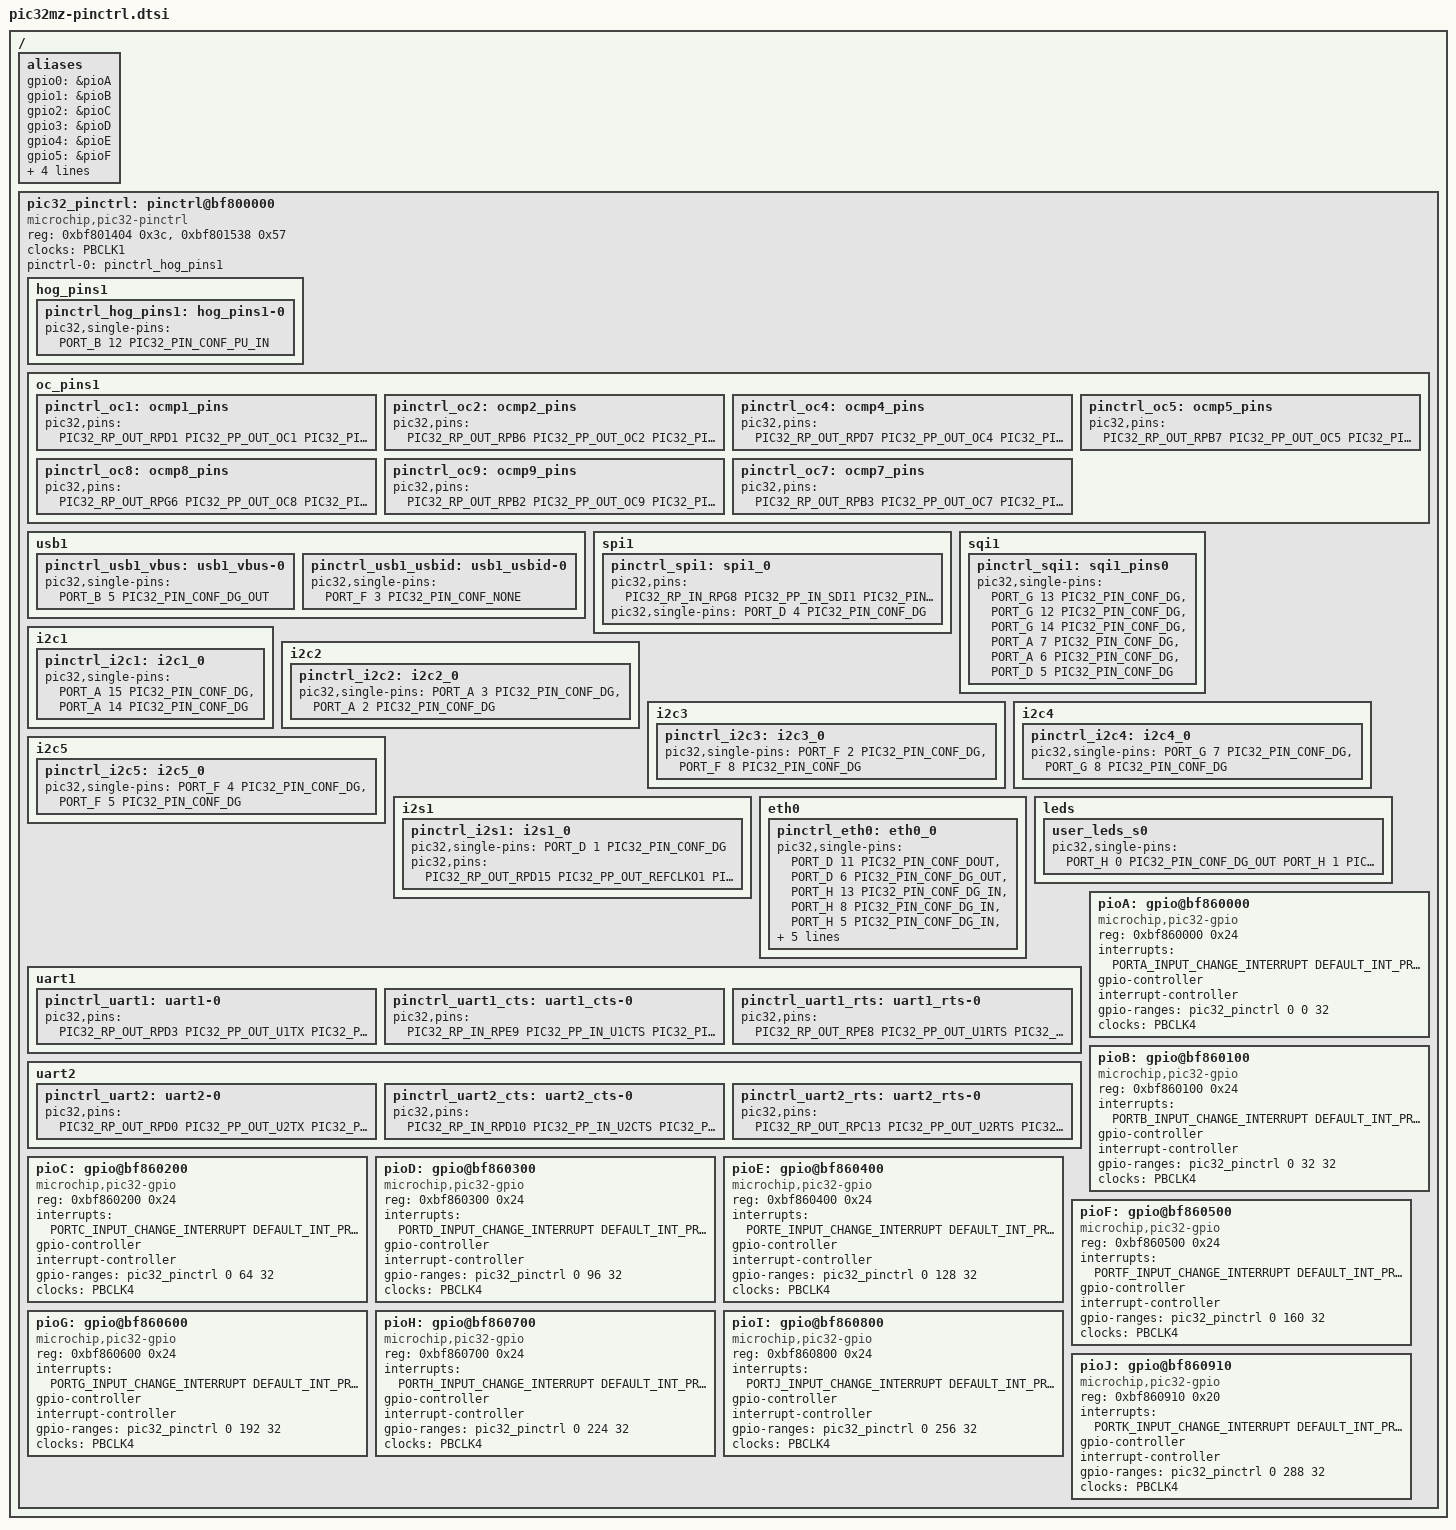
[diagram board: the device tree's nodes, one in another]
/*
 *  Device Tree Source for PIC32MZ pinctrl and gpio.
 *
 *  Copyright (C) 2014 Microchip,
 *                2014 Sorin-Andrei Pistirica <andrei.pistirica@microchip.com>,
 *
 * Licensed under GPLv2 or later.
 */

#include <dt-bindings/pinctrl/pic32.h>
#include <dt-bindings/gpio/gpio.h>
#include <dt-bindings/interrupt-controller/microchip,pic32mz-evic.h>

/ {
	aliases {
		gpio0 = &pioA;
		gpio1 = &pioB;
		gpio2 = &pioC;
		gpio3 = &pioD;
		gpio4 = &pioE;
		gpio5 = &pioF;
		gpio6 = &pioG;
		gpio7 = &pioH;
		gpio8 = &pioI; /*J*/
		gpio9 = &pioJ; /*K*/
	};

	pic32_pinctrl: pinctrl@bf800000{
		#address-cells = <1>;
		#size-cells = <1>;
		#gpio-range-cells = <3>;
		compatible = "microchip,pic32-pinctrl", "simple-bus";
		ranges;
		reg = <0xbf801404 0x3c>, /* in  */
		      <0xbf801538 0x57>; /* out */
		clocks = <&PBCLK1>;
		pinctrl-0 = <&pinctrl_hog_pins1>;
		pinctrl-names = "default";

		/* functions */
		hog_pins1 {
			/* sw1 - hog pins */
			pinctrl_hog_pins1: hog_pins1-0 {
				pic32,single-pins = <PORT_B 12 PIC32_PIN_CONF_PU_IN>;
			};
		};
		oc_pins1 {
			pinctrl_oc1: ocmp1_pins {
				pic32,pins = <PIC32_RP_OUT_RPD1 PIC32_PP_OUT_OC1 PIC32_PIN_CONF_DG_OUT>;
			};
			pinctrl_oc2: ocmp2_pins {
				pic32,pins = <PIC32_RP_OUT_RPB6 PIC32_PP_OUT_OC2 PIC32_PIN_CONF_DG_OUT>;
			};
			pinctrl_oc4: ocmp4_pins {
				pic32,pins = <PIC32_RP_OUT_RPD7 PIC32_PP_OUT_OC4 PIC32_PIN_CONF_DG_OUT>;
			};
			pinctrl_oc5: ocmp5_pins {
				pic32,pins = <PIC32_RP_OUT_RPB7 PIC32_PP_OUT_OC5 PIC32_PIN_CONF_DG_OUT>;
			};
			pinctrl_oc8: ocmp8_pins {
				pic32,pins = <PIC32_RP_OUT_RPG6 PIC32_PP_OUT_OC8 PIC32_PIN_CONF_DG_OUT>;
			};
			pinctrl_oc9: ocmp9_pins {
				pic32,pins = <PIC32_RP_OUT_RPB2 PIC32_PP_OUT_OC9 PIC32_PIN_CONF_DG_OUT>;
			};
#if 0
			pinctrl_oc3: ocmp3_pins {
				pic32,pins = <PIC32_RP_OUT_RPB3 PIC32_PP_OUT_OC3 PIC32_PIN_CONF_DG_OUT>;
			};
			pinctrl_oc6: ocmp6_pins {
				pic32,pins = <PIC32_RP_OUT_RPB3 PIC32_PP_OUT_OC6 PIC32_PIN_CONF_DG_OUT>;
			};
#endif
			pinctrl_oc7: ocmp7_pins {
				pic32,pins = <PIC32_RP_OUT_RPB3 PIC32_PP_OUT_OC7 PIC32_PIN_CONF_DG_OUT>;
			};
		};
		usb1 {
			pinctrl_usb1_vbus: usb1_vbus-0 {
				pic32,single-pins = <PORT_B 5 PIC32_PIN_CONF_DG_OUT>;
			};

			pinctrl_usb1_usbid: usb1_usbid-0 {
				pic32,single-pins = <PORT_F 3 PIC32_PIN_CONF_NONE>;
			};

		};

		spi1 {
			pinctrl_spi1: spi1_0 {
				pic32,pins = <PIC32_RP_IN_RPG8 PIC32_PP_IN_SDI1 PIC32_PIN_CONF_DG_IN
					PIC32_RP_OUT_RPB10 PIC32_PP_OUT_SDO1 PIC32_PIN_CONF_DG_OUT>;
				pic32,single-pins = <PORT_D 4 PIC32_PIN_CONF_DG>; /* spi1_cs */
			};
		};

		sqi1 {
			pinctrl_sqi1: sqi1_pins0 {
				pic32,single-pins =
					<PORT_G 13 PIC32_PIN_CONF_DG>, /* D0 */
					<PORT_G 12 PIC32_PIN_CONF_DG>, /* D1 */
					<PORT_G 14 PIC32_PIN_CONF_DG>, /* D2 */
					<PORT_A 7 PIC32_PIN_CONF_DG>, /* D3 */
					<PORT_A 6 PIC32_PIN_CONF_DG>, /* CLK */
					/*<PORT_D 4 PIC32_PIN_CONF_DG>, *//* CS0 */
					<PORT_D 5 PIC32_PIN_CONF_DG> /* CS1 */
				;
			};
		};

		i2c1 {
			pinctrl_i2c1: i2c1_0 {
				pic32,single-pins = <PORT_A 15 PIC32_PIN_CONF_DG>,
				<PORT_A 14 PIC32_PIN_CONF_DG>;
			};
		};

		i2c2 {
			pinctrl_i2c2: i2c2_0 {
				pic32,single-pins = <PORT_A 3 PIC32_PIN_CONF_DG>,
				<PORT_A 2 PIC32_PIN_CONF_DG>;
			};
		};

		i2c3 {
			pinctrl_i2c3: i2c3_0 {
				pic32,single-pins = <PORT_F 2 PIC32_PIN_CONF_DG>,
				<PORT_F 8 PIC32_PIN_CONF_DG>;
			};
		};

		i2c4 {
			pinctrl_i2c4: i2c4_0 {
				pic32,single-pins = <PORT_G 7 PIC32_PIN_CONF_DG>,
				<PORT_G 8 PIC32_PIN_CONF_DG>;
			};
		};

		i2c5 {
			pinctrl_i2c5: i2c5_0 {
				pic32,single-pins = <PORT_F 4 PIC32_PIN_CONF_DG>,
				<PORT_F 5 PIC32_PIN_CONF_DG>;
			};
		};

		i2s1 {
			pinctrl_i2s1: i2s1_0 {
				pic32,single-pins = <PORT_D 1 PIC32_PIN_CONF_DG>;

				pic32,pins = <PIC32_RP_OUT_RPD15 PIC32_PP_OUT_REFCLKO1 PIC32_PIN_CONF_DG
				PIC32_RP_IN_RPD14 PIC32_PP_IN_SDI1 PIC32_PIN_CONF_DG
				PIC32_RP_OUT_RPB10 PIC32_PP_OUT_SDO1 PIC32_PIN_CONF_DG
				PIC32_RP_OUT_RPB15 PIC32_PP_OUT_SS1 PIC32_PIN_CONF_DG>;
			};
		};

		eth0 {
			pinctrl_eth0: eth0_0 {
				pic32,single-pins = <PORT_D 11 PIC32_PIN_CONF_DOUT>,
				<PORT_D 6 PIC32_PIN_CONF_DG_OUT>,
				<PORT_H 13 PIC32_PIN_CONF_DG_IN>,
				<PORT_H 8 PIC32_PIN_CONF_DG_IN>,
				<PORT_H 5 PIC32_PIN_CONF_DG_IN>,
				<PORT_H 4 PIC32_PIN_CONF_DG_IN>,
				<PORT_J 11 PIC32_PIN_CONF_DG_IN>,
				<PORT_J 9 PIC32_PIN_CONF_DG_OUT>,
				<PORT_J 8 PIC32_PIN_CONF_DG_OUT>,
				<PORT_J 1 PIC32_PIN_CONF_DG_IN>;
			};
		};

		leds {

			user_leds_s0: user_leds_s0 {
				pic32,single-pins = <
                                PORT_H 0 PIC32_PIN_CONF_DG_OUT
                                PORT_H 1 PIC32_PIN_CONF_DG_OUT
				PORT_H 2 PIC32_PIN_CONF_DG_OUT>;
			};
		};

		uart1 {
			/* uart1: pin groups */
			pinctrl_uart1: uart1-0 {
				pic32,pins =
					<PIC32_RP_OUT_RPD3 PIC32_PP_OUT_U1TX PIC32_PIN_CONF_DG_OUT
					 PIC32_RP_IN_RPD2 PIC32_PP_IN_U1RX PIC32_PIN_CONF_DG_IN>;
			};

			pinctrl_uart1_cts: uart1_cts-0 {
				pic32,pins =
					<PIC32_RP_IN_RPE9 PIC32_PP_IN_U1CTS PIC32_PIN_CONF_DG_IN>;
			};
			pinctrl_uart1_rts: uart1_rts-0 {
				pic32,pins =
					<PIC32_RP_OUT_RPE8 PIC32_PP_OUT_U1RTS PIC32_PIN_CONF_DG_OUT>;
			};
		};

		uart2 {
			/* uart2: pin groups */
			pinctrl_uart2: uart2-0 {
				pic32,pins =
					<PIC32_RP_OUT_RPD0 PIC32_PP_OUT_U2TX PIC32_PIN_CONF_DG_OUT
					 PIC32_RP_IN_RPB0 PIC32_PP_IN_U2RX PIC32_PIN_CONF_DG_IN>;
			};

			pinctrl_uart2_cts: uart2_cts-0 {
				pic32,pins =
					<PIC32_RP_IN_RPD10 PIC32_PP_IN_U2CTS PIC32_PIN_CONF_DG_IN>;
			};
			pinctrl_uart2_rts: uart2_rts-0 {
				pic32,pins =
					<PIC32_RP_OUT_RPC13 PIC32_PP_OUT_U2RTS PIC32_PIN_CONF_DG_OUT>;
			};
		};

		/* GPIO banks */
		pioA: gpio@bf860000 {
			compatible = "microchip,pic32-gpio";
			reg = <0xbf860000 0x24>;
			interrupts = <PORTA_INPUT_CHANGE_INTERRUPT DEFAULT_INT_PRI IRQ_TYPE_LEVEL_HIGH>;
			#gpio-cells = <2>;
			gpio-controller;
			interrupt-controller;
			#interrupt-cells = <2>;
			gpio-ranges = <&pic32_pinctrl 0 0 32>;
			clocks = <&PBCLK4>;
		};

		pioB: gpio@bf860100 {
			compatible = "microchip,pic32-gpio";
			reg = <0xbf860100 0x24>;
			interrupts = <PORTB_INPUT_CHANGE_INTERRUPT DEFAULT_INT_PRI IRQ_TYPE_LEVEL_HIGH>;
			#gpio-cells = <2>;
			gpio-controller;
			interrupt-controller;
			#interrupt-cells = <2>;
			gpio-ranges = <&pic32_pinctrl 0 32 32>;
			clocks = <&PBCLK4>;
		};

		pioC: gpio@bf860200 {
			compatible = "microchip,pic32-gpio";
			reg = <0xbf860200 0x24>;
			interrupts = <PORTC_INPUT_CHANGE_INTERRUPT DEFAULT_INT_PRI IRQ_TYPE_LEVEL_HIGH>;
			#gpio-cells = <2>;
			gpio-controller;
			interrupt-controller;
			#interrupt-cells = <2>;
			gpio-ranges = <&pic32_pinctrl 0 64 32>;
			clocks = <&PBCLK4>;
		};

		pioD: gpio@bf860300 {
			compatible = "microchip,pic32-gpio";
			reg = <0xbf860300 0x24>;
			interrupts = <PORTD_INPUT_CHANGE_INTERRUPT DEFAULT_INT_PRI IRQ_TYPE_LEVEL_HIGH>;
			#gpio-cells = <2>;
			gpio-controller;
			interrupt-controller;
			#interrupt-cells = <2>;
			gpio-ranges = <&pic32_pinctrl 0 96 32>;
			clocks = <&PBCLK4>;
		};

		pioE: gpio@bf860400 {
			compatible = "microchip,pic32-gpio";
			reg = <0xbf860400 0x24>;
			interrupts = <PORTE_INPUT_CHANGE_INTERRUPT DEFAULT_INT_PRI IRQ_TYPE_LEVEL_HIGH>;
			#gpio-cells = <2>;
			gpio-controller;
			interrupt-controller;
			#interrupt-cells = <2>;
			gpio-ranges = <&pic32_pinctrl 0 128 32>;
			clocks = <&PBCLK4>;
		};

		pioF: gpio@bf860500 {
			compatible = "microchip,pic32-gpio";
			reg = <0xbf860500 0x24>;
			interrupts = <PORTF_INPUT_CHANGE_INTERRUPT DEFAULT_INT_PRI IRQ_TYPE_LEVEL_HIGH>;
			#gpio-cells = <2>;
			gpio-controller;
			interrupt-controller;
			#interrupt-cells = <2>;
			gpio-ranges = <&pic32_pinctrl 0 160 32>;
			clocks = <&PBCLK4>;
		};

		pioG: gpio@bf860600 {
			compatible = "microchip,pic32-gpio";
			reg = <0xbf860600 0x24>;
			interrupts = <PORTG_INPUT_CHANGE_INTERRUPT DEFAULT_INT_PRI IRQ_TYPE_LEVEL_HIGH>;
			#gpio-cells = <2>;
			gpio-controller;
			interrupt-controller;
			#interrupt-cells = <2>;
			gpio-ranges = <&pic32_pinctrl 0 192 32>;
			clocks = <&PBCLK4>;
		};

		pioH: gpio@bf860700 {
			compatible = "microchip,pic32-gpio";
			reg = <0xbf860700 0x24>;
			interrupts = <PORTH_INPUT_CHANGE_INTERRUPT DEFAULT_INT_PRI IRQ_TYPE_LEVEL_HIGH>;
			#gpio-cells = <2>;
			gpio-controller;
			interrupt-controller;
			#interrupt-cells = <2>;
			gpio-ranges = <&pic32_pinctrl 0 224 32>;
			clocks = <&PBCLK4>;
		};

		pioI: gpio@bf860800 { /* H + 1 = I -> J */
			compatible = "microchip,pic32-gpio";
			reg = <0xbf860800 0x24>;
			interrupts = <PORTJ_INPUT_CHANGE_INTERRUPT DEFAULT_INT_PRI IRQ_TYPE_LEVEL_HIGH>;
			#gpio-cells = <2>;
			gpio-controller;
			interrupt-controller;
			#interrupt-cells = <2>;
			gpio-ranges = <&pic32_pinctrl 0 256 32>;
			clocks = <&PBCLK4>;
		};

		pioJ: gpio@bf860910 { /* I + 1 = J -> K */
			compatible = "microchip,pic32-gpio";
			reg = <0xbf860910 0x20>;
			interrupts = <PORTK_INPUT_CHANGE_INTERRUPT DEFAULT_INT_PRI IRQ_TYPE_LEVEL_HIGH>;
			#gpio-cells = <2>;
			gpio-controller;
			interrupt-controller;
			#interrupt-cells = <2>;
			gpio-ranges = <&pic32_pinctrl 0 288 32>;
			clocks = <&PBCLK4>;
		};
	};
};
